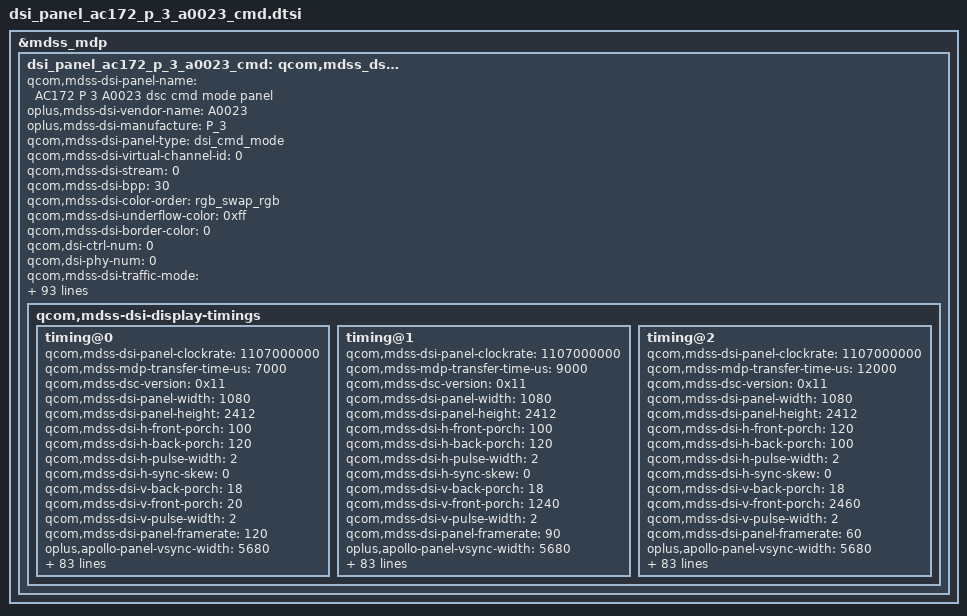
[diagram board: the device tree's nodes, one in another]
&mdss_mdp {
	dsi_panel_ac172_p_3_a0023_cmd: qcom,mdss_dsi_panel_ac172_p_3_a0023_cmd {
		qcom,mdss-dsi-panel-name = "AC172 P 3 A0023 dsc cmd mode panel";
		oplus,mdss-dsi-vendor-name = "A0023";
		oplus,mdss-dsi-manufacture = "P_3";
		qcom,mdss-dsi-panel-type = "dsi_cmd_mode";
		qcom,mdss-dsi-virtual-channel-id = <0>;
		qcom,mdss-dsi-stream = <0>;
		qcom,mdss-dsi-bpp = <30>;
		qcom,mdss-dsi-color-order = "rgb_swap_rgb";
		qcom,mdss-dsi-underflow-color = <0xff>;
		qcom,mdss-dsi-border-color = <0>;
		qcom,dsi-ctrl-num = <0>;
		qcom,dsi-phy-num = <0>;
		qcom,mdss-dsi-traffic-mode = "non_burst_sync_event";
		qcom,mdss-dsi-lane-map = "lane_map_0123";
		qcom,mdss-dsi-bllp-eof-power-mode;
		qcom,mdss-dsi-bllp-power-mode;
		qcom,mdss-dsi-lane-0-state;
		qcom,mdss-dsi-lane-1-state;
		qcom,mdss-dsi-lane-2-state;
		qcom,mdss-dsi-lane-3-state;
		qcom,mdss-dsi-dma-trigger = "trigger_sw";
		qcom,mdss-dsi-mdp-trigger = "none";
		qcom,mdss-dsi-bl-inverted-dbv;
		qcom,mdss-dsi-reset-sequence = <1 10>, <0 10>, <1 10>;
		qcom,mdss-dsi-te-pin-select = <1>;
		qcom,mdss-dsi-te-dcs-command = <1>;
		qcom,mdss-dsi-te-check-enable;
		qcom,mdss-dsi-te-using-te-pin;
		qcom,mdss-dsi-wr-mem-start = <0x2c>;
		qcom,mdss-dsi-wr-mem-continue = <0x3c>;
		qcom,mdss-dsi-panel-hdr-enabled;
		qcom,mdss-dsi-panel-hdr-color-primaries = <15000 15500 34000
			16000 13250 34500 7500 3000>;
		qcom,mdss-dsi-panel-peak-brightness = <4300000>;
		qcom,mdss-dsi-panel-blackness-level = <1023>;
		qcom,mdss-pan-physical-width-dimension = <70>;
		qcom,mdss-pan-physical-height-dimension = <155>;
		qcom,bl-update-flag = "delay_until_first_frame";

		qcom,mdss-dsi-display-timings {
			timing@0{
				qcom,mdss-dsi-panel-clockrate = <1107000000>;
				qcom,mdss-mdp-transfer-time-us = <7000>;
				qcom,mdss-dsc-version = <0x11>;
				qcom,mdss-dsi-panel-width = <1080>;
				qcom,mdss-dsi-panel-height = <2412>;
				qcom,mdss-dsi-h-front-porch = <100>;
				qcom,mdss-dsi-h-back-porch = <120>;
				qcom,mdss-dsi-h-pulse-width = <2>;
				qcom,mdss-dsi-h-sync-skew = <0>;
				qcom,mdss-dsi-v-back-porch = <18>;
				qcom,mdss-dsi-v-front-porch = <20>;
				qcom,mdss-dsi-v-pulse-width = <2>;
				qcom,mdss-dsi-panel-framerate = <120>;
				/* Apollo vsync config, need to measure TE signal */
				oplus,apollo-panel-vsync-width = <5680>;
				oplus,apollo-panel-vsync-period = <16850>;

				/* ofp config */
				oplus,ofp-need-to-sync-data-in-aod-unlocking;
				oplus,ofp-aod-off-insert-black-frame = <1>;
				oplus,ofp-aod-off-black-frame-total-time = <42>;
				oplus,ofp-need-to-separate-backlight;
				oplus,ofp-backlight-on-period = <1>;

				qcom,mdss-dsi-on-command = [
					39 00 00 42 00 00 03 F0 5A 5A
					39 00 00 42 00 00 07 91 00 00 00 80 80 80
					39 00 00 42 00 00 0A 86 00 10 00 00 00 00 00 00 00
					39 00 00 42 00 00 02 03 01
					0A 00 00 42 00 00 5D 11 00 00 AB 30 80 09 6C 04 38 00 0C 02 1C 02 1C 02 00 02 0E 00 20 01 1F 00 07 00 0C 08 BB 08 7A 18 00 10 F0 07 10 20 00 06 0F 0F 33 0E 1C 2A 38 46 54 62 69 70 77 79 7B 7D 7E 01 02 22 00 2A 40 2A BE 3A FC 3A FA 3A F8 3B 38 3B 78 3B B6 4B F6 4C 34 4C 74 5C 74 8C F4 00 00 00 00 00
					39 00 00 42 00 00 05 2A 00 00 04 37
					39 00 00 42 00 00 05 2B 00 00 09 6B
					39 00 00 42 00 00 03 43 10 02
					39 00 00 42 00 00 03 44 09 32
					39 00 00 42 00 00 02 35 00
					39 00 00 42 00 00 02 53 20
					39 00 00 02 78 00 01 11
					39 00 00 42 00 00 03 F0 5A 5A
					39 00 00 42 00 00 02 B0 50
					39 00 00 42 00 00 02 F2 25
					39 00 00 42 00 00 02 B0 00
					39 00 00 42 00 00 2D B3 12 00 00 0F 00 BF 00 31 09 B0 03 1A 00 5A 00 BF A0 13 42 00 7D 0F 12 14 00 03 02 6B 00 00 04 78 04 78 04 20 00 00 00 00 00 00 00 00
					39 00 00 42 00 00 03 DE 1B 04
					39 00 00 42 00 00 02 C9 1F
					39 00 00 42 00 00 02 B0 26
					39 00 00 42 00 00 02 CD F9
					39 00 00 42 00 00 02 B0 6D
					39 00 00 42 00 00 02 F2 02
					39 00 00 42 00 00 0E F7 FD 03 A2 77 33 22 01 00 7D 03 00 37 0B
					39 00 00 42 00 00 02 E2 8E
					39 00 00 02 1E 00 01 29
					39 00 00 42 00 00 02 B0 26
					39 00 00 42 00 00 02 B2 00
					39 00 00 02 00 00 03 F0 A5 A5
				];
				qcom,mdss-dsi-timing-switch-command = [
					/* 120hz Transition */
					39 00 00 02 00 00 03 F0 5A 5A
					39 00 00 02 00 00 09 86 00 10 00 00 00 00 00 00
					39 00 00 02 00 00 03 F0 A5 A5
				];
				qcom,mdss-dsi-off-command = [
					39 00 00 02 00 00 03 F0 5A 5A
					39 00 00 02 00 00 03 90 00 00
					39 00 00 02 05 00 01 28
					39 00 00 02 14 00 03 82 80 19
					39 00 00 02 00 00 03 82 00 00
					39 00 00 02 50 00 01 10
				];
				qcom,mdss-dsi-lp1-command = [
					/*	AOD Switch */
					39 00 00 02 00 00 05 51 00 00 0F FE
					/* AOD Mode ON */
					39 00 00 02 00 00 03 F0 5A 5A
					39 01 00 02 00 00 02 90 01
					39 00 00 02 00 00 03 F0 A5 A5
				];
				qcom,mdss-dsi-nolp-command = [
					/* AOD Mode OFF */
					39 00 00 02 00 00 03 F0 5A 5A
					39 00 00 02 00 00 02 90 00
					39 00 00 02 00 00 03 F0 A5 A5
					39 00 00 02 28 00 05 51 00 00 00 00
				];
				qcom,mdss-dsi-aod-high-mode-command = [
					/* AOD High Mode, 50nit */
					39 00 00 02 00 00 05 51 04 5D 0D BB
				];
				qcom,mdss-dsi-aod-low-mode-command = [
					/* AOD Low Mode 10nit */
					39 00 00 02 00 00 05 51 01 EE 0A 01
				];
				qcom,mdss-dsi-hbm-on-command = [
					39 00 00 02 00 00 03 51 0E FA
				];
				qcom,mdss-dsi-hbm-off-command = [
					39 00 00 02 00 00 03 51 0D BB
				];
				qcom,dsi-panel-date-switch-command = [
					39 00 00 02 00 00 03 F0 5A 5A
				];
				qcom,mdss-dsi-default-switch-page-command = [
					39 00 00 02 00 00 03 F0 A5 A5
				];
				qcom,mdss-dsi-esd-switch-page-command = [
					39 00 00 02 00 00 03 F0 5A 5A
				];
				qcom,mdss-dsi-esd-offset-location-command = [
					39 00 00 50 00 00 02 B0 A4
				];
				qcom,mdss-dsi-esd-offset-location-command-state = "dsi_lp_mode";
				qcom,mdss-dsi-esd-switch-page-command-state = "dsi_lp_mode";
				qcom,mdss-dsi-esd-switch-page-state = "dsi_lp_mode";
				qcom,mdss-dsi-aod-hbm-on-command-state = "dsi_lp_mode";
				qcom,mdss-dsi-aod-hbm-off-command-state = "dsi_lp_mode";
				qcom,mdss-dsi-hbm-on-command-state = "dsi_lp_mode";
				qcom,mdss-dsi-seed-off-command-state = "dsi_lp_mode";
				qcom,mdss-dsi-seed-0-command-state = "dsi_lp_mode";
				qcom,mdss-dsi-seed-1-command-state = "dsi_lp_mode";
				qcom,mdss-dsi-seed-2-command-state = "dsi_lp_mode";
				qcom,mdss-dsi-lp1-command-state = "dsi_lp_mode";
				qcom,mdss-dsi-lhbm-pressed-icon-gamma-command-state = "dsi_lp_mode";
				qcom,mdss-dsi-lhbm-pressed-icon-grayscale-command-state = "dsi_lp_mode";
				qcom,mdss-dsi-lhbm-pressed-icon-on-command-state = "dsi_lp_mode";
				qcom,mdss-dsi-lhbm-pressed-icon-off-command-state = "dsi_lp_mode";
				qcom,mdss-dsi-aod-high-mode-command-state = "dsi_lp_mode";
				qcom,mdss-dsi-aod-low-mode-command-state = "dsi_lp_mode";
				qcom,mdss-dsi-nolp-command-state = "dsi_lp_mode";
				qcom,mdss-dsi-timing-switch-command-state = "dsi_lp_mode";
				qcom,mdss-dsi-on-command-state = "dsi_lp_mode";
				qcom,mdss-dsi-off-command-state = "dsi_lp_mode";
				// qcom,dsi-panel-date-switch-command-state = "dsi_lp_mode";
				qcom,mdss-dsi-default-switch-page-command-state = "dsi_lp_mode";
				qcom,compression-mode = "dsc";
				qcom,mdss-dsc-slice-height = <12>;
				qcom,mdss-dsc-slice-width = <540>;
				qcom,mdss-dsc-slice-per-pkt = <2>;
				qcom,mdss-dsc-bit-per-component = <10>;
				qcom,mdss-dsc-bit-per-pixel = <8>;
				qcom,mdss-dsc-block-prediction-enable;
			};
			timing@1{
				qcom,mdss-dsi-panel-clockrate = <1107000000>;
				qcom,mdss-mdp-transfer-time-us = <9000>;
				qcom,mdss-dsc-version = <0x11>;
				qcom,mdss-dsi-panel-width = <1080>;
				qcom,mdss-dsi-panel-height = <2412>;
				qcom,mdss-dsi-h-front-porch = <100>;
				qcom,mdss-dsi-h-back-porch = <120>;
				qcom,mdss-dsi-h-pulse-width = <2>;
				qcom,mdss-dsi-h-sync-skew = <0>;
				qcom,mdss-dsi-v-back-porch = <18>;
				qcom,mdss-dsi-v-front-porch = <1240>;
				qcom,mdss-dsi-v-pulse-width = <2>;
				qcom,mdss-dsi-panel-framerate = <90>;
				/* Apollo vsync config, need to measure TE signal */
				oplus,apollo-panel-vsync-width = <5680>;
				oplus,apollo-panel-vsync-period = <16850>;

				/* ofp config */
				oplus,ofp-need-to-sync-data-in-aod-unlocking;
				oplus,ofp-aod-off-insert-black-frame = <1>;
				oplus,ofp-aod-off-black-frame-total-time = <45>;
				oplus,ofp-need-to-separate-backlight;
				oplus,ofp-backlight-on-period = <1>;

				qcom,mdss-dsi-on-command = [
					39 00 00 42 00 00 03 F0 5A 5A
					39 00 00 42 00 00 07 91 00 00 00 80 80 80
					39 00 00 42 00 00 0A 86 00 11 00 00 00 00 00 00 00
					39 00 00 42 00 00 02 03 01
					0A 00 00 42 00 00 5D 11 00 00 AB 30 80 09 6C 04 38 00 0C 02 1C 02 1C 02 00 02 0E 00 20 01 1F 00 07 00 0C 08 BB 08 7A 18 00 10 F0 07 10 20 00 06 0F 0F 33 0E 1C 2A 38 46 54 62 69 70 77 79 7B 7D 7E 01 02 22 00 2A 40 2A BE 3A FC 3A FA 3A F8 3B 38 3B 78 3B B6 4B F6 4C 34 4C 74 5C 74 8C F4 00 00 00 00 00
					39 00 00 42 00 00 05 2A 00 00 04 37
					39 00 00 42 00 00 05 2B 00 00 09 6B
					39 00 00 42 00 00 03 43 10 02
					39 00 00 42 00 00 03 44 09 32
					39 00 00 42 00 00 02 35 00
					39 00 00 42 00 00 02 53 20
					39 00 00 02 78 00 01 11
					39 00 00 42 00 00 03 F0 5A 5A
					39 00 00 42 00 00 02 B0 50
					39 00 00 42 00 00 02 F2 25
					39 00 00 42 00 00 02 B0 00
					39 00 00 42 00 00 2D B3 12 00 00 0F 00 BF 00 31 09 B0 03 1A 00 5A 00 BF A0 13 42 00 7D 0F 12 14 00 03 02 6B 00 00 04 78 04 78 04 20 00 00 00 00 00 00 00 00
					39 00 00 42 00 00 03 DE 1B 04
					39 00 00 42 00 00 02 C9 1F
					39 00 00 42 00 00 02 B0 26
					39 00 00 42 00 00 02 CD F9
					39 00 00 42 00 00 02 B0 6D
					39 00 00 42 00 00 02 F2 02
					39 00 00 42 00 00 0E F7 FD 03 A2 77 33 22 01 00 7D 03 00 37 0B
					39 00 00 42 00 00 02 E2 8E
					39 00 00 02 1E 00 01 29
					39 00 00 42 00 00 02 B0 26
					39 00 00 42 00 00 02 B2 00
					39 00 00 02 00 00 03 F0 A5 A5
				];
				qcom,mdss-dsi-timing-switch-command = [
					/* 90hz Transition */
					39 00 00 02 00 00 03 F0 5A 5A
					39 00 00 02 00 00 09 86 00 11 00 00 00 00 00 00
					39 00 00 02 00 00 03 F0 A5 A5
				];
				qcom,mdss-dsi-off-command = [
					39 00 00 02 00 00 03 F0 5A 5A
					39 00 00 02 00 00 03 90 00 00
					39 00 00 02 05 00 01 28
					39 00 00 02 14 00 03 82 80 19
					39 00 00 02 00 00 03 82 00 00
					39 00 00 02 50 00 01 10
				];
				qcom,mdss-dsi-lp1-command = [
					/*	AOD Switch */
					39 00 00 02 00 00 05 51 00 00 0F FE
					/* AOD Mode ON */
					39 00 00 02 00 00 03 F0 5A 5A
					39 00 00 02 00 00 02 90 01
					39 00 00 02 00 00 03 F0 A5 A5
				];
				qcom,mdss-dsi-nolp-command = [
					/* AOD Mode OFF */
					39 00 00 02 00 00 03 F0 5A 5A
					39 00 00 02 00 00 02 90 00
					39 00 00 02 00 00 03 F0 A5 A5
					39 00 00 02 28 00 05 51 00 00 00 00
				];
				qcom,mdss-dsi-aod-high-mode-command = [
					/* AOD High Mode, 50nit */
					39 00 00 02 00 00 05 51 04 5D 0D BB
				];
				qcom,mdss-dsi-aod-low-mode-command = [
					/* AOD Low Mode 10nit */
					39 00 00 02 00 00 05 51 01 EE 0A 01
				];
				qcom,mdss-dsi-hbm-on-command = [
					39 00 00 02 00 00 03 51 0E FA
				];
				qcom,mdss-dsi-hbm-off-command = [
					39 00 00 02 00 00 03 51 0D BB
				];
				qcom,dsi-panel-date-switch-command = [
					39 00 00 02 00 00 03 F0 5A 5A
				];
				qcom,mdss-dsi-default-switch-page-command = [
					39 00 00 02 00 00 03 F0 A5 A5
				];
				qcom,mdss-dsi-esd-switch-page-command = [
					39 00 00 02 00 00 03 F0 5A 5A
				];
				qcom,mdss-dsi-esd-offset-location-command = [
					39 00 00 50 00 00 02 B0 A4
				];
				qcom,mdss-dsi-esd-offset-location-command-state = "dsi_lp_mode";
				qcom,mdss-dsi-esd-switch-page-command-state = "dsi_lp_mode";
				qcom,mdss-dsi-esd-switch-page-state = "dsi_lp_mode";
				qcom,mdss-dsi-aod-hbm-on-command-state = "dsi_lp_mode";
				qcom,mdss-dsi-aod-hbm-off-command-state = "dsi_lp_mode";
				qcom,mdss-dsi-hbm-on-command-state = "dsi_lp_mode";
				qcom,mdss-dsi-seed-off-command-state = "dsi_lp_mode";
				qcom,mdss-dsi-seed-0-command-state = "dsi_lp_mode";
				qcom,mdss-dsi-seed-1-command-state = "dsi_lp_mode";
				qcom,mdss-dsi-seed-2-command-state = "dsi_lp_mode";
				qcom,mdss-dsi-lp1-command-state = "dsi_lp_mode";
				qcom,mdss-dsi-lhbm-pressed-icon-gamma-command-state = "dsi_lp_mode";
				qcom,mdss-dsi-lhbm-pressed-icon-grayscale-command-state = "dsi_lp_mode";
				qcom,mdss-dsi-lhbm-pressed-icon-on-command-state = "dsi_lp_mode";
				qcom,mdss-dsi-lhbm-pressed-icon-off-command-state = "dsi_lp_mode";
				qcom,mdss-dsi-aod-high-mode-command-state = "dsi_lp_mode";
				qcom,mdss-dsi-aod-low-mode-command-state = "dsi_lp_mode";
				qcom,mdss-dsi-nolp-command-state = "dsi_lp_mode";
				qcom,mdss-dsi-timing-switch-command-state = "dsi_lp_mode";
				qcom,mdss-dsi-on-command-state = "dsi_lp_mode";
				qcom,mdss-dsi-off-command-state = "dsi_lp_mode";
				// qcom,dsi-panel-date-switch-command-state = "dsi_lp_mode";
				qcom,mdss-dsi-default-switch-page-command-state = "dsi_lp_mode";
				qcom,compression-mode = "dsc";
				qcom,mdss-dsc-slice-height = <12>;
				qcom,mdss-dsc-slice-width = <540>;
				qcom,mdss-dsc-slice-per-pkt = <2>;
				qcom,mdss-dsc-bit-per-component = <10>;
				qcom,mdss-dsc-bit-per-pixel = <8>;
				qcom,mdss-dsc-block-prediction-enable;
			};
			timing@2{
				qcom,mdss-dsi-panel-clockrate = <1107000000>;
				qcom,mdss-mdp-transfer-time-us = <12000>;
				qcom,mdss-dsc-version = <0x11>;
				qcom,mdss-dsi-panel-width = <1080>;
				qcom,mdss-dsi-panel-height = <2412>;
				qcom,mdss-dsi-h-front-porch = <120>;
				qcom,mdss-dsi-h-back-porch = <100>;
				qcom,mdss-dsi-h-pulse-width = <2>;
				qcom,mdss-dsi-h-sync-skew = <0>;
				qcom,mdss-dsi-v-back-porch = <18>;
				qcom,mdss-dsi-v-front-porch = <2460>;
				qcom,mdss-dsi-v-pulse-width = <2>;
				qcom,mdss-dsi-panel-framerate = <60>;
				/* Apollo vsync config, need to measure TE signal */
				oplus,apollo-panel-vsync-width = <5680>;
				oplus,apollo-panel-vsync-period = <16850>;

				/* ofp config */
				oplus,ofp-need-to-sync-data-in-aod-unlocking;
				oplus,ofp-aod-off-insert-black-frame = <2>;
				oplus,ofp-aod-off-black-frame-total-time = <59>;
				oplus,ofp-need-to-separate-backlight;
				oplus,ofp-backlight-on-period = <1>;

				qcom,mdss-dsi-on-command = [
					39 00 00 42 00 00 03 F0 5A 5A
					39 00 00 42 00 00 07 91 00 00 00 80 80 80
					39 00 00 42 00 00 0A 86 00 12 00 00 00 00 00 00 00
					39 00 00 42 00 00 02 03 01
					0A 00 00 42 00 00 5D 11 00 00 AB 30 80 09 6C 04 38 00 0C 02 1C 02 1C 02 00 02 0E 00 20 01 1F 00 07 00 0C 08 BB 08 7A 18 00 10 F0 07 10 20 00 06 0F 0F 33 0E 1C 2A 38 46 54 62 69 70 77 79 7B 7D 7E 01 02 22 00 2A 40 2A BE 3A FC 3A FA 3A F8 3B 38 3B 78 3B B6 4B F6 4C 34 4C 74 5C 74 8C F4 00 00 00 00 00
					39 00 00 42 00 00 05 2A 00 00 04 37
					39 00 00 42 00 00 05 2B 00 00 09 6B
					39 00 00 42 00 00 03 43 10 02
					39 00 00 42 00 00 03 44 09 32
					39 00 00 42 00 00 02 35 00
					39 00 00 42 00 00 02 53 20
					39 00 00 02 78 00 01 11
					39 00 00 42 00 00 03 F0 5A 5A
					39 00 00 42 00 00 02 B0 50
					39 00 00 42 00 00 02 F2 25
					39 00 00 42 00 00 02 B0 00
					39 00 00 42 00 00 2D B3 12 00 00 0F 00 BF 00 31 09 B0 03 1A 00 5A 00 BF A0 13 42 00 7D 0F 12 14 00 03 02 6B 00 00 04 78 04 78 04 20 00 00 00 00 00 00 00 00
					39 00 00 42 00 00 03 DE 1B 04
					39 00 00 42 00 00 02 C9 1F
					39 00 00 42 00 00 02 B0 26
					39 00 00 42 00 00 02 CD F9
					39 00 00 42 00 00 02 B0 6D
					39 00 00 42 00 00 02 F2 02
					39 00 00 42 00 00 0E F7 FD 03 A2 77 33 22 01 00 7D 03 00 37 0B
					39 00 00 42 00 00 02 E2 8E
					39 00 00 02 1E 00 01 29
					39 00 00 42 00 00 02 B0 26
					39 00 00 42 00 00 02 B2 00
					39 00 00 02 00 00 03 F0 A5 A5
				];
				qcom,mdss-dsi-timing-switch-command = [
					/* 60hz Transition */
					39 00 00 02 00 00 03 F0 5A 5A
					39 00 00 02 00 00 09 86 00 12 00 00 00 00 00 00
					39 00 00 00 00 00 03 F0 A5 A5
				];
				qcom,mdss-dsi-off-command = [
					39 00 00 02 00 00 03 F0 5A 5A
					39 00 00 02 00 00 03 90 00 00
					39 00 00 02 05 00 01 28
					39 00 00 02 14 00 03 82 80 19
					39 00 00 02 00 00 03 82 00 00
					39 00 00 02 50 00 01 10

				];
				qcom,mdss-dsi-lp1-command = [
					/*	AOD Switch */
					39 00 00 02 00 00 05 51 00 00 0F FE
					/* AOD Mode ON */
					39 00 00 02 00 00 03 F0 5A 5A
					39 00 00 02 00 00 02 90 01
					39 00 00 02 00 00 03 F0 A5 A5
				];
				qcom,mdss-dsi-nolp-command = [
					/* AOD Mode OFF */
					39 00 00 02 00 00 03 F0 5A 5A
					39 00 00 02 00 00 02 90 00
					39 00 00 02 00 00 03 F0 A5 A5
					39 00 00 02 28 00 05 51 00 00 00 00
				];
				qcom,mdss-dsi-aod-high-mode-command = [
					/* AOD High Mode, 50nit */
					39 00 00 02 00 00 05 51 04 5D 0D BB
				];
				qcom,mdss-dsi-aod-low-mode-command = [
					/* AOD Low Mode 10nit */
					39 00 00 02 00 00 05 51 01 EE 0A 01
				];
				qcom,mdss-dsi-hbm-on-command = [
					39 00 00 02 00 00 03 51 0E FA
				];
				qcom,mdss-dsi-hbm-off-command = [
					39 00 00 02 00 00 03 51 0D BB
				];
				qcom,dsi-panel-date-switch-command = [
					39 00 00 02 00 00 03 F0 5A 5A
				];
				qcom,mdss-dsi-default-switch-page-command = [
					39 00 00 02 00 00 03 F0 A5 A5
				];
				qcom,mdss-dsi-esd-switch-page-command = [
					39 00 00 02 00 00 03 F0 5A 5A
				];
				qcom,mdss-dsi-esd-offset-location-command = [
					39 00 00 50 00 00 02 B0 A4
				];
				qcom,mdss-dsi-esd-offset-location-command-state = "dsi_lp_mode";
				qcom,mdss-dsi-esd-switch-page-command-state = "dsi_lp_mode";
				qcom,mdss-dsi-esd-switch-page-state = "dsi_lp_mode";
				qcom,mdss-dsi-aod-hbm-on-command-state = "dsi_lp_mode";
				qcom,mdss-dsi-aod-hbm-off-command-state = "dsi_lp_mode";
				qcom,mdss-dsi-hbm-on-command-state = "dsi_lp_mode";
				qcom,mdss-dsi-seed-off-command-state = "dsi_lp_mode";
				qcom,mdss-dsi-seed-0-command-state = "dsi_lp_mode";
				qcom,mdss-dsi-seed-1-command-state = "dsi_lp_mode";
				qcom,mdss-dsi-seed-2-command-state = "dsi_lp_mode";
				qcom,mdss-dsi-lp1-command-state = "dsi_lp_mode";
				qcom,mdss-dsi-lhbm-pressed-icon-gamma-command-state = "dsi_lp_mode";
				qcom,mdss-dsi-lhbm-pressed-icon-grayscale-command-state = "dsi_lp_mode";
				qcom,mdss-dsi-lhbm-pressed-icon-on-command-state = "dsi_lp_mode";
				qcom,mdss-dsi-lhbm-pressed-icon-off-command-state = "dsi_lp_mode";
				qcom,mdss-dsi-aod-high-mode-command-state = "dsi_lp_mode";
				qcom,mdss-dsi-aod-low-mode-command-state = "dsi_lp_mode";
				qcom,mdss-dsi-nolp-command-state = "dsi_lp_mode";
				qcom,mdss-dsi-timing-switch-command-state = "dsi_lp_mode";
				qcom,mdss-dsi-on-command-state = "dsi_lp_mode";
				qcom,mdss-dsi-off-command-state = "dsi_lp_mode";
				// qcom,dsi-panel-date-switch-command-state = "dsi_lp_mode";
				qcom,mdss-dsi-default-switch-page-command-state = "dsi_lp_mode";
				qcom,compression-mode = "dsc";
				qcom,mdss-dsc-slice-height = <12>;
				qcom,mdss-dsc-slice-width = <540>;
				qcom,mdss-dsc-slice-per-pkt = <2>;
				qcom,mdss-dsc-bit-per-component = <10>;
				qcom,mdss-dsc-bit-per-pixel = <8>;
				qcom,mdss-dsc-block-prediction-enable;
			};
		};
	};
};

&dsi_panel_ac172_p_3_a0023_cmd {
	qcom,panel-supply-entries = <&Avatar_M_dsi_panel_pwr_supply_oled>;
	qcom,mdss-dsi-bl-pmic-control-type = "bl_ctrl_dcs";
	qcom,mdss-dsi-bl-min-level = <1>;
	qcom,mdss-dsi-bl-max-level = <4094>;
	qcom,mdss-brightness-max-level = <4094>;
	qcom,mdss-dsi-bl-hbm-min-level = <3327>;
	oplus,dsi-bl-normal-max-level = <3515>;
	oplus,dsi-brightness-normal-max-level = <3515>;
	oplus,dsi-brightness-default-level = <1843>;
	qcom,platform-te-gpio = <&tlmm 23 0>;
	qcom,platform-reset-gpio = <&tlmm 47 0>;
	qcom,platform-panel-vout-gpio = <&tlmm 101 0>;
	oplus,dsi-fod-brightness = <0 0xff>,
			<2 0xee>,
			<4 0xee>,
			<6 0xee>,
			<8 0xec>,
			<10 0xec>,
			<22 0xec>,
			<40 0xec>,
			<65 0xec>,
			<107 0xec>,
			<139 0xeb>,
			<173 0xea>,
			<204 0xe9>,
			<237 0xe8>,
			<267 0xe7>,
			<304 0xe6>,
			<335 0xe5>,
			<365 0xe4>,
			<395 0xe3>,
			<424 0xe2>,
			<454 0xe1>,
			<482 0xe0>,
			<507 0xdf>,
			<536 0xde>,
			<554 0xdd>,
			<568 0xdc>,
			<587 0xdb>,
			<603 0xda>,
			<620 0xd9>,
			<640 0xd8>,
			<654 0xd7>,
			<670 0xd6>,
			<690 0xd5>,
			<708 0xd4>,
			<724 0xd3>,
			<746 0xd2>,
			<764 0xd1>,
			<781 0xd0>,
			<804 0xcf>,
			<824 0xce>,
			<842 0xcd>,
			<861 0xcc>,
			<881 0xcb>,
			<901 0xca>,
			<921 0xc9>,
			<942 0xc8>,
			<959 0xc7>,
			<977 0xc6>,
			<995 0xc5>,
			<1015 0xc4>,
			<1033 0xc3>,
			<1054 0xc2>,
			<1078 0xc1>,
			<1098 0xc0>,
			<1121 0xbf>,
			<1137 0xbe>,
			<1159 0xbd>,
			<1178 0xbc>,
			<1197 0xbb>,
			<1222 0xba>,
			<1241 0xb9>,
			<1260 0xb8>,
			<1281 0xb7>,
			<1307 0xb6>,
			<1325 0xb5>,
			<1345 0xb4>,
			<1351 0xb3>,
			<1379 0xb2>,
			<1402 0xb1>,
			<1607 0xa6>,
			<1792 0x9c>,
			<1995 0x91>,
			<2203 0x85>,
			<2405 0x7a>,
			<2600 0x6f>,
			<2800 0x63>,
			<3000 0x56>,
			<3200 0x49>,
			<3400 0x3d>,
			<3515 0x35>;

	qcom,esd-check-default-cmds-switch-enabled;
	qcom,esd-check-enabled;
	qcom,mdss-dsi-panel-status-check-mode = "reg_read";
	qcom,mdss-dsi-panel-status-command = [
		06 01 00 01 00 00 01 B1
		06 01 00 01 00 00 01 0A
		06 01 00 01 00 00 01 03
		06 01 00 01 00 00 01 0B
		06 01 00 01 00 00 01 0D
		06 01 00 01 00 00 01 8B
		06 01 00 01 00 00 01 90
		06 01 00 01 00 00 01 96
		06 01 00 01 00 00 01 A2
	];
	qcom,mdss-dsi-panel-status-command-state = "dsi_lp_mode";
	qcom,mdss-dsi-panel-status-value = <0x06 0x9C 0x01 0x00 0x00 0x00 0x00 0x00 0x11 0x00 0x00 0xAB>;
	qcom,mdss-dsi-panel-status-read-length = <1 1 1 1 1 1 1 1 4>;
	oplus,mdss-dsi-panel-status-match-modes = <0x00000000>;

	qcom,ulps-enabled;
	qcom,suspend-ulps-enabled;
	qcom,dsi-select-clocks = "pll_byte_clk0", "pll_dsi_clk0";


	/* ofp config */
	oplus,ofp-fp-type = <0x08>;
	oplus,ofp-need-to-wait-data-before-aod-on;

	/* serail number config */
	oplus,dsi-serial-number-enabled;
	oplus,dsi-serial-number-index= <0>;
	oplus,dsi-serial-number-switch-page;
	oplus,dsi-serial-number-reg= <0xBA>;
	oplus,dsi-serial-number-read-count= <7>;

	/* panel id compatibility */
	oplus,panel_init_compatibility_enable;

	qcom,mdss-dsi-display-timings {
		/* 120hz 553.5mhz */
		timing@0{
			qcom,mdss-dsi-panel-phy-timings = [00 24 0A 0A 1A 18 0A 0A 09 02 04 00 1E 0F];
			qcom,display-topology = <1 1 1>;
			qcom,default-topology-index = <0>;
		};
		/* 90hz 553.5mhz */
		timing@1{
			qcom,mdss-dsi-panel-phy-timings = [00 24 0A 0A 1A 18 0A 0A 09 02 04 00 1E 0F];
			qcom,display-topology = <1 1 1>;
			qcom,default-topology-index = <0>;
		};
		/* 60hz 553.5mhz */
		timing@2{
			qcom,mdss-dsi-panel-phy-timings = [00 24 0A 0A 1A 18 0A 0A 09 02 04 00 1E 0F];
			qcom,display-topology = <1 1 1>;
			qcom,default-topology-index = <0>;
		};
	};
};

&dsi_panel_ac172_p_3_a0023_cmd {
	qcom,panel_voltage_vddi_name = "vddi";
	qcom,panel_voltage_vddi = <0 1650000 1800000 1950000>;
	qcom,panel_voltage_vddr_name = "vddr";
	qcom,panel_voltage_vddr = <1 1450000 1500000 1600000>;
};
